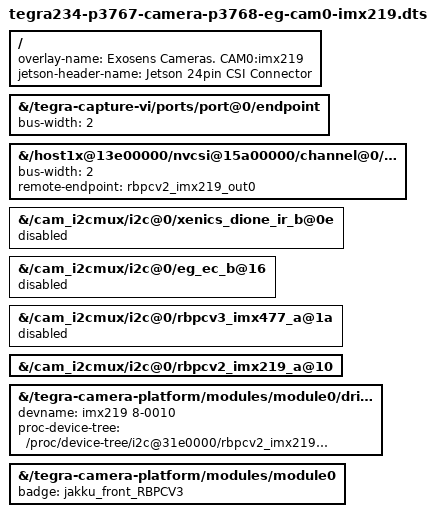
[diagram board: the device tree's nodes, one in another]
// SPDX-License-Identifier: GPL-2.0-only

/dts-v1/;
/plugin/;

#include <dt-common/jetson/tegra234-p3767-0000-common.h>

/ {
	overlay-name = "Exosens Cameras. CAM0:imx219";
	jetson-header-name = "Jetson 24pin CSI Connector";
	compatible = JETSON_COMPATIBLE_P3768;

	fragment@00 {
		target-path = "/tegra-capture-vi/ports/port@0/endpoint";
		__overlay__ {
			bus-width=<2>;
		};
	};

	fragment@1 {
		target-path = "/host1x@13e00000/nvcsi@15a00000/channel@0/ports/port@0/endpoint@0";
		__overlay__ {
			bus-width=<2>;
			remote-endpoint = <&rbpcv2_imx219_out0>;
		};
	};

   // Disable Dione cameras
	fragment@2 {
		target-path = "/cam_i2cmux/i2c@0/xenics_dione_ir_b@0e";
		__overlay__ {
         status = "disabled";
		};
	};

   // Disable EngineCore cameras
	fragment@3 {
		target-path = "/cam_i2cmux/i2c@0/eg_ec_b@16";
		__overlay__ {
         status = "disabled";
		};
	};

  // Disable other cameras 
	fragment@4 {
		target-path = "/cam_i2cmux/i2c@0/rbpcv3_imx477_a@1a";
		__overlay__ {
         status = "disabled";
		};
	};

	// Enable imx219
	fragment@5 {
		target-path = "/cam_i2cmux/i2c@0/rbpcv2_imx219_a@10";
		__overlay__ {
         status = "okay";
		};
	};

	fragment@6 {
		target-path = "/tegra-camera-platform/modules/module0/drivernode0";
		__overlay__ {
			devname = "imx219 8-0010";
			proc-device-tree = "/proc/device-tree/i2c@31e0000/rbpcv2_imx219_a@16";
		};
	};

	fragment@7 {
		target-path = "/tegra-camera-platform/modules/module0";
		__overlay__ {
			badge = "jakku_front_RBPCV3";
		};
	};


};
